# bao1x register map
Vendor: baochip; File version: 1.0
Registers are 32-bit, read-write, reset 0x0 unless marked. A register's access mark holds for its fields unless they carry their own. Offsets are from the block's base; [hi:lo] are bit positions; <NAME> marks a mode.

## PKE
Base 0x4002C000
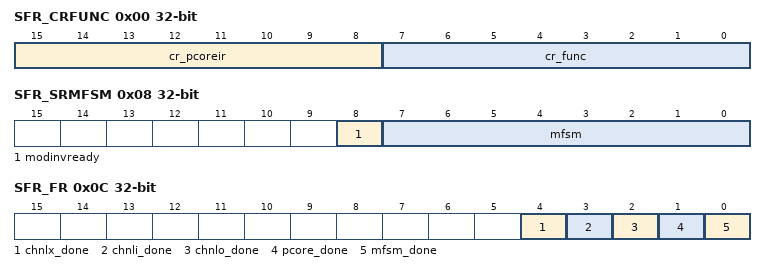
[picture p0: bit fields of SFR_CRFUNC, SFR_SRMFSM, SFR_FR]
0x00 SFR_CRFUNC — See `pke.sv#L294 <https://github.com/baochip/baochip-1x/blob/main/rtl/modules/cr ypto_top/rtl/pke.sv#L294>`__ (line numbers are approximate)
  [15:8] cr_pcoreir — cr_pcoreir read/write control register
  [7:0] cr_func — cr_func read/write control register
0x04 SFR_AR2 — See `pke.sv#L296 <https://github.com/baochip/baochip-1x/blob/main/rtl/modules/cr ypto_top/rtl/pke.sv#L296>`__ (line numbers are approximate)
  [31:0] sfr_ar2 — sfr_ar2 performs action on write of value: 0xff
0x08 SFR_SRMFSM — See `pke.sv#L297 <https://github.com/baochip/baochip-1x/blob/main/rtl/modules/cr ypto_top/rtl/pke.sv#L297>`__ (line numbers are approximate)
  [8] modinvready — modinvready read only status register
  [7:0] mfsm — mfsm read only status register
0x0C SFR_FR — See `pke.sv#L298 <https://github.com/baochip/baochip-1x/blob/main/rtl/modules/cr ypto_top/rtl/pke.sv#L298>`__ (line numbers are approximate)
  [4] chnlx_done — chnlx_done flag register. `1` means event happened, write back `1` in respective bit position to clear the flag
  [3] chnli_done — chnli_done flag register. `1` means event happened, write back `1` in respective bit position to clear the flag
  [2] chnlo_done — chnlo_done flag register. `1` means event happened, write back `1` in respective bit position to clear the flag
  [1] pcore_done — pcore_done flag register. `1` means event happened, write back `1` in respective bit position to clear the flag
  [0] mfsm_done — mfsm_done flag register. `1` means event happened, write back `1` in respective bit position to clear the flag
0x10 SFR_OPTNW — See `pke.sv#L300 <https://github.com/baochip/baochip-1x/blob/main/rtl/modules/cr ypto_top/rtl/pke.sv#L300>`__ (line numbers are approximate)
  [13:0] sfr_optnw — sfr_optnw read/write control register
0x14 SFR_OPTEW — See `pke.sv#L301 <https://github.com/baochip/baochip-1x/blob/main/rtl/modules/cr ypto_top/rtl/pke.sv#L301>`__ (line numbers are approximate)
  [13:0] sfr_optew — sfr_optew read/write control register
0x18 SFR_OPTRW — See `pke.sv#L302 <https://github.com/baochip/baochip-1x/blob/main/rtl/modules/cr ypto_top/rtl/pke.sv#L302>`__ (line numbers are approximate)
  [9:0] sfr_optrw — sfr_optrw read/write control register
0x1C SFR_OPTLTX — See `pke.sv#L303 <https://github.com/baochip/baochip-1x/blob/main/rtl/modules/cr ypto_top/rtl/pke.sv#L303>`__ (line numbers are approximate)
  [4:0] sfr_optltx — sfr_optltx read/write control register
0x20 SFR_OPTMASK — See `pke.sv#L305 <https://github.com/baochip/baochip-1x/blob/main/rtl/modules/cr ypto_top/rtl/pke.sv#L305>`__ (line numbers are approximate)
  [15:0] sfr_optmask — sfr_optmask read/write control register
0x24 SFR_MIMMCR — See `pke.sv#L306 <https://github.com/baochip/baochip-1x/blob/main/rtl/modules/cr ypto_top/rtl/pke.sv#L306>`__ (line numbers are approximate)
  [8:0] sfr_mimmcr — sfr_mimmcr read/write control register
0x30 SFR_SEGPTR_PTRID_PCON — See `pke.sv#L307 <https://github.com/baochip/baochip-1x/blob/main/rtl/modules/cr ypto_top/rtl/pke.sv#L307>`__ (line numbers are approximate)
  [11:0] PTRID_PCON — cr_segptrstart read/write control register
0x34 SFR_SEGPTR_PTRID_PIB0 — See `pke.sv#L307 <https://github.com/baochip/baochip-1x/blob/main/rtl/modules/cr ypto_top/rtl/pke.sv#L307>`__ (line numbers are approximate)
  [11:0] PTRID_PIB0 — cr_segptrstart read/write control register
0x38 SFR_SEGPTR_PTRID_PIB1 — See `pke.sv#L307 <https://github.com/baochip/baochip-1x/blob/main/rtl/modules/cr ypto_top/rtl/pke.sv#L307>`__ (line numbers are approximate)
  [11:0] PTRID_PIB1 — cr_segptrstart read/write control register
0x3C SFR_SEGPTR_PTRID_PKB — See `pke.sv#L307 <https://github.com/baochip/baochip-1x/blob/main/rtl/modules/cr ypto_top/rtl/pke.sv#L307>`__ (line numbers are approximate)
  [11:0] PTRID_PKB — cr_segptrstart read/write control register
0x40 SFR_SEGPTR_PTRID_POB — See `pke.sv#L307 <https://github.com/baochip/baochip-1x/blob/main/rtl/modules/cr ypto_top/rtl/pke.sv#L307>`__ (line numbers are approximate)
  [11:0] PTRID_POB — cr_segptrstart read/write control register
0x50 SFR_TICKCYC — See `pke.sv#L309 <https://github.com/baochip/baochip-1x/blob/main/rtl/modules/cr ypto_top/rtl/pke.sv#L309>`__ (line numbers are approximate)
  [7:0] sfr_tickcyc — sfr_tickcyc read/write control register
0x54 SFR_TICKCNT — See `pke.sv#L310 <https://github.com/baochip/baochip-1x/blob/main/rtl/modules/cr ypto_top/rtl/pke.sv#L310>`__ (line numbers are approximate)
  [31:0] sfr_tickcnt — sfr_tickcnt read only status register
0x60 SFR_MASKSEED — See `pke.sv#L312 <https://github.com/baochip/baochip-1x/blob/main/rtl/modules/cr ypto_top/rtl/pke.sv#L312>`__ (line numbers are approximate)
  [31:0] sfr_maskseed — sfr_maskseed read/write control register
0x64 SFR_MASKSEEDAR — See `pke.sv#L313 <https://github.com/baochip/baochip-1x/blob/main/rtl/modules/cr ypto_top/rtl/pke.sv#L313>`__ (line numbers are approximate)
  [31:0] sfr_maskseedar — sfr_maskseedar performs action on write of value: 0x5a
